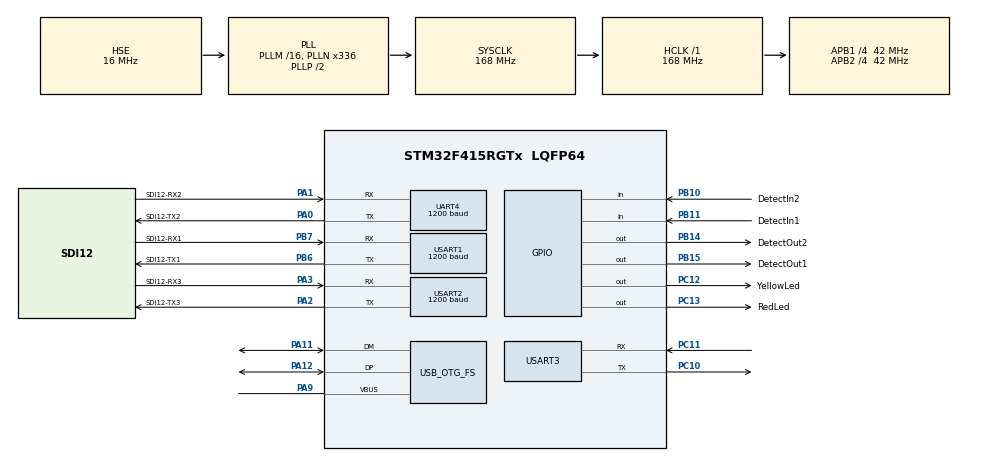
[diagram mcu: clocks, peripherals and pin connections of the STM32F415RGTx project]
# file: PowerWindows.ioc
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Mcu.Family=STM32F4
Mcu.Name=STM32F415RGTx
Mcu.Package=LQFP64
NVIC.OTG_FS_IRQn=true\:0\:0\:false\:false\:true
NVIC.PriorityGroup=NVIC_PRIORITYGROUP_4
NVIC.UART4_IRQn=true\:0\:0\:false\:false\:true
NVIC.USART1_IRQn=true\:0\:0\:false\:false\:true
NVIC.USART2_IRQn=true\:0\:0\:false\:false\:true
NVIC.USART3_IRQn=true\:0\:0\:false\:false\:true
PA0-WKUP.GPIO_Label=SDI12-TX2
PA0-WKUP.GPIO_Mode=GPIO_MODE_AF_PP
PA0-WKUP.GPIO_PuPd=GPIO_NOPULL
PA0-WKUP.GPIO_Speed=GPIO_SPEED_FREQ_LOW
PA0-WKUP.Mode=LIN
PA0-WKUP.Signal=UART4_TX
PA1.GPIO_Label=SDI12-RX2
PA1.Mode=LIN
PA1.Signal=UART4_RX
PA11.Mode=Device_Only
PA11.Signal=USB_OTG_FS_DM
PA12.Mode=Device_Only
PA12.Signal=USB_OTG_FS_DP
PA13.Mode=Serial_Wire
PA13.Signal=SYS_JTMS-SWDIO
PA14.Mode=Serial_Wire
PA14.Signal=SYS_JTCK-SWCLK
PA2.GPIO_Label=SDI12-TX3
PA2.Mode=LIN
PA2.Signal=USART2_TX
PA3.GPIO_Label=SDI12-RX3
PA3.GPIO_Speed=GPIO_SPEED_FREQ_LOW
PA3.Mode=LIN
PA3.Signal=USART2_RX
PA9.Mode=Activate_VBUS
PA9.Signal=USB_OTG_FS_VBUS
PB10.GPIO_Label=DetectIn2
PB10.GPIO_PuPd=GPIO_PULLUP
PB10.Signal=GPIO_Input
PB11.GPIO_Label=DetectIn1
PB11.GPIO_PuPd=GPIO_PULLUP
PB11.Signal=GPIO_Input
PB14.GPIO_Label=DetectOut2
PB14.GPIO_ModeDefaultOutputPP=GPIO_MODE_OUTPUT_OD
PB14.GPIO_PuPd=GPIO_PULLUP
PB14.Signal=GPIO_Output
PB15.GPIO_Label=DetectOut1
PB15.GPIO_ModeDefaultOutputPP=GPIO_MODE_OUTPUT_OD
PB15.GPIO_PuPd=GPIO_PULLUP
PB15.Signal=GPIO_Output
PB6.GPIO_Label=SDI12-TX1
PB6.GPIO_Mode=GPIO_MODE_AF_PP
PB6.GPIO_Speed=GPIO_SPEED_FREQ_LOW
PB6.Mode=LIN
PB6.Signal=USART1_TX
PB7.GPIO_Label=SDI12-RX1
PB7.GPIO_Speed=GPIO_SPEED_FREQ_LOW
PB7.Mode=LIN
PB7.Signal=USART1_RX
PC10.Mode=Asynchronous
PC10.Signal=USART3_TX
PC11.Mode=Asynchronous
PC11.Signal=USART3_RX
PC12.GPIO_Label=YellowLed
PC12.Signal=GPIO_Output
PC13-ANTI_TAMP.GPIO_Label=RedLed
PC13-ANTI_TAMP.Signal=GPIO_Output
PC14-OSC32_IN.Mode=LSE-External-Oscillator
PC14-OSC32_IN.Signal=RCC_OSC32_IN
PC15-OSC32_OUT.Mode=LSE-External-Oscillator
PC15-OSC32_OUT.Signal=RCC_OSC32_OUT
PH0-OSC_IN.Mode=HSE-External-Oscillator
PH0-OSC_IN.Signal=RCC_OSC_IN
PH1-OSC_OUT.Mode=HSE-External-Oscillator
PH1-OSC_OUT.Signal=RCC_OSC_OUT
ProjectManager.HeapSize=0x200
ProjectManager.StackSize=0x400
ProjectManager.TargetToolchain=EWARM
RCC.48MHZClocksFreq_Value=48000000
RCC.AHBFreq_Value=168000000
RCC.APB1CLKDivider=RCC_HCLK_DIV4
RCC.APB1Freq_Value=42000000
RCC.APB1TimFreq_Value=84000000
RCC.APB2CLKDivider=RCC_HCLK_DIV4
RCC.APB2Freq_Value=42000000
RCC.APB2TimFreq_Value=84000000
RCC.CortexFreq_Value=168000000
RCC.HCLKFreq_Value=168000000
RCC.HSE_VALUE=16000000
RCC.HSI_VALUE=16000000
RCC.PLLN=336
RCC.PLLQ=7
RCC.SYSCLKFreq_VALUE=168000000
RCC.SYSCLKSource=RCC_SYSCLKSOURCE_PLLCLK
RCC.VCOOutputFreq_Value=336000000
TIM2.OCMode_1=TIM_OCMODE_ACTIVE
TIM2.Period=999
TIM2.Prescaler=0
TIM2.Pulse-Output\ Compare1\ No\ Output=1
TIM2.TIM_MasterOutputTrigger=TIM_TRGO_OC1
TIM2.TIM_MasterSlaveMode=TIM_MASTERSLAVEMODE_DISABLE
TIM7.Period=999
TIM7.Prescaler=167
UART4.BaudRate=1200
UART4.BreakDetectLength=UART_LINBREAKDETECTLENGTH_11B
UART4.Parity=PARITY_EVEN
USART1.BaudRate=1200
USART1.BreakDetectLength=UART_LINBREAKDETECTLENGTH_11B
USART1.Parity=PARITY_EVEN
USART2.BaudRate=1200
USART2.BreakDetectLength=UART_LINBREAKDETECTLENGTH_11B
USART2.Parity=PARITY_EVEN
USB_DEVICE.CLASS_NAME_FS=CDC
USB_DEVICE.VirtualMode-CDC_FS=Cdc
USB_DEVICE.VirtualModeFS=Cdc_FS
USB_OTG_FS.VirtualMode=Device_Only
VP_TIM2_VS_ClockSourceINT.Mode=Internal
VP_TIM2_VS_no_output1.Mode=Output Compare1 No Output
VP_TIM7_VS_ClockSourceINT.Mode=Enable_Timer
VP_USB_DEVICE_VS_USB_DEVICE_CDC_FS.Mode=CDC_FS
board=PowerWindows

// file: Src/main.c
/**
  ******************************************************************************
  * File Name          : main.c
  * Description        : Main program body
  ******************************************************************************
  *
  * Copyright (c) 2017 STMicroelectronics International N.V.
  * All rights reserved.
  *
  * Redistribution and use in source and binary forms, with or without
  * modification, are permitted, provided that the following conditions are met:
  *
  * 1. Redistribution of source code must retain the above copyright notice,
  *    this list of conditions and the following disclaimer.
  * 2. Redistributions in binary form must reproduce the above copyright notice,
  *    this list of conditions and the following disclaimer in the documentation
  *    and/or other materials provided with the distribution.
  * 3. Neither the name of STMicroelectronics nor the names of other
  *    contributors to this software may be used to endorse or promote products
  *    derived from this software without specific written permission.
  * 4. This software, including modifications and/or derivative works of this
  *    software, must execute solely and exclusively on microcontroller or
  *    microprocessor devices manufactured by or for STMicroelectronics.
  * 5. Redistribution and use of this software other than as permitted under
  *    this license is void and will automatically terminate your rights under
  *    this license.
  *
  * THIS SOFTWARE IS PROVIDED BY STMICROELECTRONICS AND CONTRIBUTORS "AS IS"
  * AND ANY EXPRESS, IMPLIED OR STATUTORY WARRANTIES, INCLUDING, BUT NOT
  * LIMITED TO, THE IMPLIED WARRANTIES OF MERCHANTABILITY, FITNESS FOR A
  * PARTICULAR PURPOSE AND NON-INFRINGEMENT OF THIRD PARTY INTELLECTUAL PROPERTY
  * RIGHTS ARE DISCLAIMED TO THE FULLEST EXTENT PERMITTED BY LAW. IN NO EVENT
  * SHALL STMICROELECTRONICS OR CONTRIBUTORS BE LIABLE FOR ANY DIRECT, INDIRECT,
  * INCIDENTAL, SPECIAL, EXEMPLARY, OR CONSEQUENTIAL DAMAGES (INCLUDING, BUT NOT
  * LIMITED TO, PROCUREMENT OF SUBSTITUTE GOODS OR SERVICES; LOSS OF USE, DATA,
  * OR PROFITS; OR BUSINESS INTERRUPTION) HOWEVER CAUSED AND ON ANY THEORY OF
  * LIABILITY, WHETHER IN CONTRACT, STRICT LIABILITY, OR TORT (INCLUDING
  * NEGLIGENCE OR OTHERWISE) ARISING IN ANY WAY OUT OF THE USE OF THIS SOFTWARE,
  * EVEN IF ADVISED OF THE POSSIBILITY OF SUCH DAMAGE.
  *
  ******************************************************************************
  */
#include "main.h"
#include "stm32f4xx_hal.h"
#include "tim.h"
#include "usart.h"
#include "usb_device.h"
#include "gpio.h"

/* USER CODE BEGIN PV */
/* Private variables ---------------------------------------------------------*/

/* USER CODE END PV */

void SystemClock_Config(void);
void Error_Handler(void);

/* USER CODE BEGIN PFP */
/* Private function prototypes -----------------------------------------------*/

/* USER CODE END PFP */

int main(void)
{

  /* MCU Configuration----------------------------------------------------------*/

  /* Reset of all peripherals, Initializes the Flash interface and the Systick. */
  HAL_Init();

  /* Configure the system clock */
  SystemClock_Config();

  /* Initialize all configured peripherals */
  MX_GPIO_Init();
  MX_USB_DEVICE_Init();
  MX_USART3_UART_Init();
  MX_TIM7_Init();
  MX_TIM2_Init();
  MX_USART1_UART_Init();
  MX_USART2_UART_Init();
  MX_UART4_Init();

  /* Infinite loop */
  /* USER CODE BEGIN WHILE */
  void cli(void);
  cli();
  /* USER CODE END WHILE */

}

/** System Clock Configuration
*/
void SystemClock_Config(void)
{

  RCC_OscInitTypeDef RCC_OscInitStruct;
  RCC_ClkInitTypeDef RCC_ClkInitStruct;

    /**Configure the main internal regulator output voltage
    */
  __HAL_RCC_PWR_CLK_ENABLE();

  __HAL_PWR_VOLTAGESCALING_CONFIG(PWR_REGULATOR_VOLTAGE_SCALE1);

    /**Initializes the CPU, AHB and APB busses clocks
    */
  RCC_OscInitStruct.OscillatorType = RCC_OSCILLATORTYPE_HSE;
  RCC_OscInitStruct.HSEState = RCC_HSE_ON;
  RCC_OscInitStruct.PLL.PLLState = RCC_PLL_ON;
  RCC_OscInitStruct.PLL.PLLSource = RCC_PLLSOURCE_HSE;
  RCC_OscInitStruct.PLL.PLLM = 16;
  RCC_OscInitStruct.PLL.PLLN = 336;
  RCC_OscInitStruct.PLL.PLLP = RCC_PLLP_DIV2;
  RCC_OscInitStruct.PLL.PLLQ = 7;
  if (HAL_RCC_OscConfig(&RCC_OscInitStruct) != HAL_OK)
  {
    Error_Handler();
  }

    /**Initializes the CPU, AHB and APB busses clocks
    */
  RCC_ClkInitStruct.ClockType = RCC_CLOCKTYPE_HCLK|RCC_CLOCKTYPE_SYSCLK
                              |RCC_CLOCKTYPE_PCLK1|RCC_CLOCKTYPE_PCLK2;
  RCC_ClkInitStruct.SYSCLKSource = RCC_SYSCLKSOURCE_PLLCLK;
  RCC_ClkInitStruct.AHBCLKDivider = RCC_SYSCLK_DIV1;
  RCC_ClkInitStruct.APB1CLKDivider = RCC_HCLK_DIV4;
  RCC_ClkInitStruct.APB2CLKDivider = RCC_HCLK_DIV4;

  if (HAL_RCC_ClockConfig(&RCC_ClkInitStruct, FLASH_LATENCY_5) != HAL_OK)
  {
    Error_Handler();
  }

    /**Configure the Systick interrupt time
    */
  HAL_SYSTICK_Config(HAL_RCC_GetHCLKFreq()/1000);

    /**Configure the Systick
    */
  HAL_SYSTICK_CLKSourceConfig(SYSTICK_CLKSOURCE_HCLK);

  /* SysTick_IRQn interrupt configuration */
  HAL_NVIC_SetPriority(SysTick_IRQn, 0, 0);
}

void Error_Handler(void)
{
  while(1)
  {
  }
}

/************************ (C) COPYRIGHT STMicroelectronics *****END OF FILE****/
